AUTOSAR XML (schema 4-2-2)
package /Components
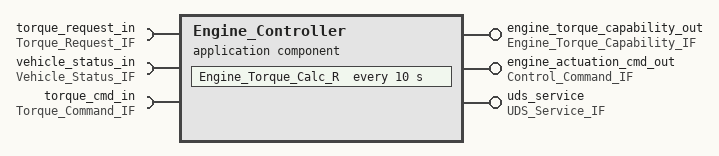
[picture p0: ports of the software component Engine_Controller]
  application sw component type Engine_Controller
    provide port engine_torque_capability_out: provided-interface=Engine_Torque_Capability_IF
    provide port engine_actuation_cmd_out: provided-interface=Control_Command_IF
    provide port uds_service: provided-interface=UDS_Service_IF
    require port torque_request_in: required-interface=Torque_Request_IF
    require port vehicle_status_in: required-interface=Vehicle_Status_IF
    require port torque_cmd_in: required-interface=Torque_Command_IF
    behavior Engine_Controller_InternalBehavior
      data received event Torque_Command_Update: start-on-event=Engine_Actuation_R
      init event Engine_Init: start-on-event=Engine_Init_R
      operation invoked event Diag_ReadData_Invoked: start-on-event=Diag_Service_R
      timing event Engine_Periodic_10ms: start-on-event=Engine_Torque_Calc_R, period=10
      4 x runnable:
        Engine_Init_R
          parameter access PA_Init_LoadCalibration: accessed-parameter=uds_service.engine_torque_capability_nm
        Engine_Torque_Calc_R
          data-read-access:
            access VA_Read_VehicleSpeed: accessed-variable=vehicle_status_in.vehicle_speed_kph
            access VA_Read_EngineRpm: accessed-variable=vehicle_status_in.engine_rpm
          data-receive-point-by-arguments:
            access VA_Arg_DriverTorqueReq: accessed-variable=torque_request_in.driver_torque_request_nm
          data-send-points:
            access VA_Send_EngineCapability: accessed-variable=engine_torque_capability_out.engine_torque_capability_nm
        Engine_Actuation_R
          data-receive-point-by-values:
            access VA_Val_EngineTorqueCmd: accessed-variable=torque_cmd_in.engine_torque_cmd_nm
          data-send-points:
            access VA_Send_ActuationCmd: accessed-variable=engine_actuation_cmd_out.engine_actuation_cmd_out
        Diag_Service_R
